# ATxmega128A3 device description
Architecture: AVR8_XMEGA; Family: AVR XMEGA
Registers are 8-bit, access not given, no defined reset value unless marked. A register's access mark holds for its fields unless they carry their own. Offsets are from the block's base; [hi:lo] are bit positions; lines under a group give offsets from that group; 'fields as' and 'values as' point back to an identical list.

## RTC — Real-Time Counter
Instances: RTC 0x0400
0x00 CTRL — Control Register
  [2:0] PRESCALER — Prescaling Factor
    0=OFF (RTC Off); 1=DIV1 (RTC Clock); 2=DIV2 (RTC Clock / 2); 3=DIV8 (RTC Clock / 8); 4=DIV16 (RTC Clock / 16); 5=DIV64 (RTC Clock / 64); 6=DIV256 (RTC Clock / 256); 7=DIV1024 (RTC Clock / 1024)
0x01 STATUS
  [0] SYNCBUSY — Synchronization Busy Flag
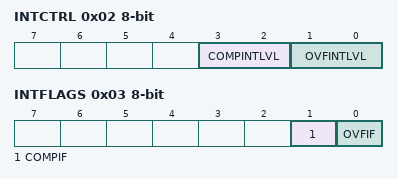
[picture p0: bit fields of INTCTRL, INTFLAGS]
0x02 INTCTRL — Interrupt Control Register
  [3:2] COMPINTLVL — Compare Match Interrupt Level
    0=OFF (Interrupt Disabled); 1=LO (Low Level); 2=MED (Medium Level); 3=HI (High Level)
  [1:0] OVFINTLVL — Overflow Interrupt Level
    values as COMPINTLVL
0x03 INTFLAGS — Interrupt Flags
  [1] COMPIF — Compare Match Interrupt Flag
  [0] OVFIF — Overflow Interrupt Flag
0x04 TEMP — Temporary register
0x08 CNT 16-bit — Count Register
0x0A PER 16-bit — Period Register
0x0C COMP 16-bit — Compare Register

## TWI — Two-Wire Interface
Instances: TWIC 0x480, TWIE 0x4A0
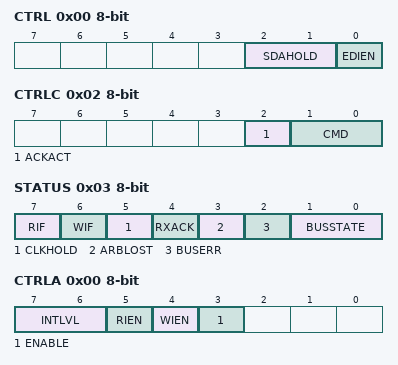
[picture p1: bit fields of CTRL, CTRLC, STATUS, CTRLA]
0x00 CTRL — TWI Common Control Register
  [2:1] SDAHOLD — SDA Hold Time Enable
    0=OFF (SDA hold time off); 1=50NS (Typical 50ns hold time); 2=300NS (Typical 300ns hold time); 3=400NS (Typical 400ns hold time)
  [0] EDIEN — External Driver Interface Enable
0x01 MASTER group — TWI master module
  0x00 CTRLA — Control Register A
    [7:6] INTLVL — Interrupt Level
      0=OFF (Interrupt Disabled); 1=LO (Low Level); 2=MED (Medium Level); 3=HI (High Level)
    [5] RIEN — Read Interrupt Enable
    [4] WIEN — Write Interrupt Enable
    [3] ENABLE — Enable TWI Master
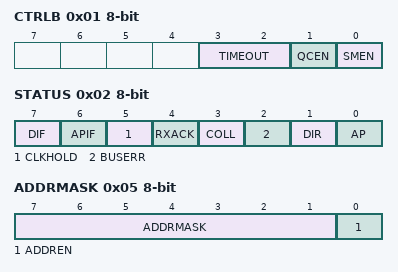
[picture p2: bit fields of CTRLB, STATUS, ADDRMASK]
  0x01 CTRLB — Control Register B
    [3:2] TIMEOUT — Inactive Bus timeout
      0=DISABLED (Bus Timeout Disabled); 1=50US (50 Microseconds); 2=100US (100 Microseconds); 3=200US (200 Microseconds)
    [1] QCEN — Quick Command Enable
    [0] SMEN — Smart Mode Enable
  0x02 CTRLC — Control Register C
    [2] ACKACT — Acknowledge Action
    [1:0] CMD — Command
      0=NOACT (No Action); 1=REPSTART (Issue Repeated Start Condition); 2=RECVTRANS (Receive or Transmit Data); 3=STOP (Issue Stop Condition)
  0x03 STATUS
    [7] RIF — Read Interrupt Flag
    [6] WIF — Write Interrupt Flag
    [5] CLKHOLD — Clock Hold
    [4] RXACK — Received Acknowledge
    [3] ARBLOST — Arbitration Lost
    [2] BUSERR — Bus Error
    [1:0] BUSSTATE
      0=UNKNOWN (Unknown Bus State); 1=IDLE (Bus is Idle); 2=OWNER (This Module Controls The Bus); 3=BUSY (The Bus is Busy)
  0x04 BAUD — Baurd Rate Control Register
  0x05 ADDR — Address Register
  0x06 DATA
0x08 SLAVE group — TWI slave module
  0x00 CTRLA — Control Register A
    [7:6] INTLVL — Interrupt Level
      values as MASTER.CTRLA.INTLVL
    [5] DIEN — Data Interrupt Enable
    [4] APIEN — Address/Stop Interrupt Enable
    [3] ENABLE — Enable TWI Slave
    [2] PIEN — Stop Interrupt Enable
    [1] PMEN — Promiscuous Mode Enable
    [0] SMEN — Smart Mode Enable
  0x01 CTRLB — Control Register B
    [2] ACKACT — Acknowledge Action
    [1:0] CMD — Command
      0=NOACT (No Action); 2=COMPTRANS (Used To Complete a Transaction); 3=RESPONSE (Used in Response to Address/Data Interrupt)
  0x02 STATUS
    [7] DIF — Data Interrupt Flag
    [6] APIF — Address/Stop Interrupt Flag
    [5] CLKHOLD — Clock Hold
    [4] RXACK — Received Acknowledge
    [3] COLL — Collision
    [2] BUSERR — Bus Error
    [1] DIR — Read/Write Direction
    [0] AP — Slave Address or Stop
  0x03 ADDR — Address Register
  0x04 DATA
  0x05 ADDRMASK — Address Mask Register
    [7:1] ADDRMASK — Address Mask
    [0] ADDREN — Address Enable

## PORTCFG — I/O port Configuration
Instances: PORTCFG 0x00B0
0x00 MPCMASK — Multi-pin Configuration Mask
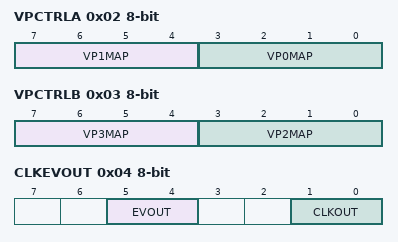
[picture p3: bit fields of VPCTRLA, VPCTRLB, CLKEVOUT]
0x02 VPCTRLA — Virtual Port Control Register A
  [7:4] VP1MAP — Virtual Port 1 Mapping
    0=PORTA (Mapped To PORTA); 1=PORTB (Mapped To PORTB); 2=PORTC (Mapped To PORTC); 3=PORTD (Mapped To PORTD); 4=PORTE (Mapped To PORTE); 5=PORTF (Mapped To PORTF); 6=PORTG (Mapped To PORTG); 7=PORTH (Mapped To PORTH); 8=PORTJ (Mapped To PORTJ); 9=PORTK (Mapped To PORTK); 10=PORTL (Mapped To PORTL); 11=PORTM (Mapped To PORTM); 12=PORTN (Mapped To PORTN); 13=PORTP (Mapped To PORTP); 14=PORTQ (Mapped To PORTQ); 15=PORTR (Mapped To PORTR)
  [3:0] VP0MAP — Virtual Port 0 Mapping
    values as VP1MAP
0x03 VPCTRLB — Virtual Port Control Register B
  [7:4] VP3MAP — Virtual Port 3 Mapping
    values as VPCTRLA.VP1MAP
  [3:0] VP2MAP — Virtual Port 2 Mapping
    values as VPCTRLA.VP1MAP
0x04 CLKEVOUT — Clock and Event Out Register
  [5:4] EVOUT — Event Output Port
    0=OFF (Event Output Disabled); 1=PC7 (Event Channel 7 Output on Port C pin 7); 2=PD7 (Event Channel 7 Output on Port D pin 7); 3=PE7 (Event Channel 7 Output on Port E pin 7)
  [1:0] CLKOUT — Clock Output Port
    0=OFF (Clock Output Disabled); 1=PC7 (Clock Output on Port C pin 7); 2=PD7 (Clock Output on Port D pin 7); 3=PE7 (Clock Output on Port E pin 7)
